# ESP32-C5 register map
Vendor: ESPRESSIF SYSTEMS (SHANGHAI) CO., LTD.; Series: ESP32 C-Series; File version: 1
CPU: RV32IMAC r0p0, little endian, no MPU, no FPU, 0 interrupt priority bits
Address unit: 32 bits
Registers are 32-bit, read-write, reset 0x0 unless marked. A register's access mark holds for its fields unless they carry their own. Offsets are from the block's base; [hi:lo] are bit positions; {n}, {i} and the like mark numbered series.

## CLINT — Core Local Interrupts
Base 0x20000000
0x1800 MSIP
  [0] MSIP — Configures the pending status of the machine software interrupt.
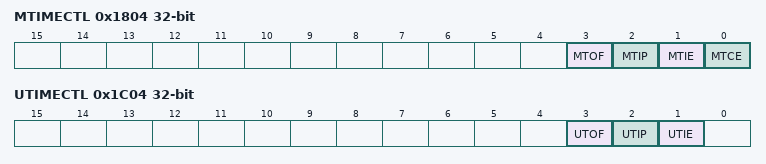
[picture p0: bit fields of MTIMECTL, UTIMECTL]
0x1804 MTIMECTL access per field
  [3] MTOF rw — Configures whether the machine timer overflows.
  [2] MTIP ro — Represents the pending status of the machine timer interrupt.
  [1] MTIE rw — Write 1 to enable the machine timer interrupt.
  [0] MTCE rw — Configures whether to enable the CLINT timer counter.
0x1808 MTIME 64-bit (reset mask 0xFFFFFFFF)
  [63:0] MTIME — Configures the 64-bit CLINT timer counter value.
0x1810 MTIMECMP 64-bit (reset mask 0xFFFFFFFF)
  [63:0] MTIMECMP — Configures the 64-bit machine timer compare value.
0x1C00 USIP
  [0] USIP — Configures the pending status of the user software interrupt.
0x1C04 UTIMECTL access per field
  [3] UTOF rw — Configures whether the user timer overflows.
  [2] UTIP ro — Represents the pending status of the user timer interrupt.
  [1] UTIE rw — Write 1 to enable the user timer interrupt.
0x1C08 UTIME 64-bit ro (reset mask 0xFFFFFFFF)
  [63:0] UTIME — Represents the read-only 64-bit CLINT timer counter value.
0x1C10 UTIMECMP 64-bit (reset mask 0xFFFFFFFF)
  [63:0] UTIMECMP — Configures the 64-bit user timer compare value.

## CLIC — Core Local Interrupt Controller
Base 0x20800000
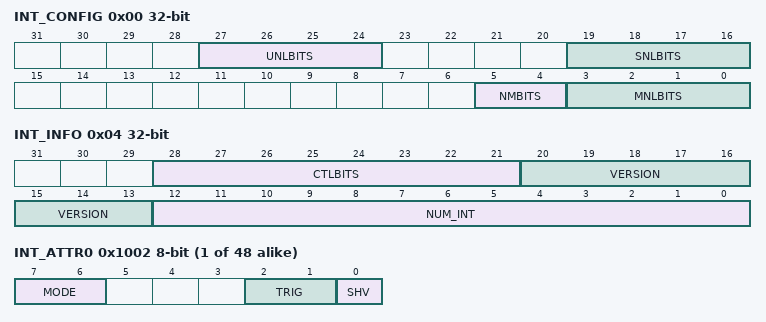
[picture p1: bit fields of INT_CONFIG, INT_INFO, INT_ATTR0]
0x00 INT_CONFIG
  [27:24] UNLBITS — User mode interrupt priority effective digits, the maximum value is 8.
  [19:16] SNLBITS — Supervisor mode interrupt priority effective digits, the maximum value is 8.
  [5:4] NMBITS — The effective number of bits in the privileged state.
  [3:0] MNLBITS — Machine mode interrupt priority effective digits, the maximum value is 8.
0x04 INT_INFO ro
  [28:21] CTLBITS — The effective bits of priority in the CLICINTCTL register.
  [20:13] VERSION — The lower 4 bits are the modified version of the hardware implementation; the upper 4 bits are the CLIC architecture version information.
  [12:0] NUM_INT — The number of interrupt sources.
{0x1000+4i} INT_IP{i} (i=0..47) 8-bit — Interrupt pending register.
  [0] INT_IP — Interrupt pending bit.
{0x1001+4i} INT_IE{i} (i=0..47) 8-bit — Interrupt enable register.
  [0] INT_IE — Interrupt enable bit.
{0x1002+4i} INT_ATTR{i} (i=0..47) 8-bit access per field — Interrupt attribute register.
  [7:6] MODE ro — Configures the privilege mode of the ith CLIC interrupt. This is hardwired to 0x3 as user mode interrupts are not supported.
  [2:1] TRIG rw — Configures the trigger type and polarity of the ith CLIC machine mode interrupt.
    0=POSITIVE_LEVEL (interrupt is positive level-triggered); 1=POSITIVE_EDGE (interrupt is positive edge-triggered); 2=NEGATIVE_LEVEL (interrupt is negative level-triggered); 3=NEGATIVE_EDGE (interrupt is negative edge-triggered)
  [0] SHV rw — Configures hardware vectoring for the ith CLIC machine mode interrupt.
    0=SOFTWARE (Not hardware vectored. Upon taking this interrupt, the CPU will jump to the address configured in mtvec.); 1=HARDWARE (Hardware vectored. Upon taking this interrupt, the CPU will jump to the word address stored at (mtvt + 4*i) relative to the base address configured in mtvt.)
{0x1003+4i} INT_CTL{i} (i=0..47) 8-bit access per field — Interrupt level control register.
  [7:5] CTL rw — Configures the level and priority of the ith CLIC machine mode interrupt.

## DS — Digital Signature
Base 0x6008C000
{0x0+4i} Y_MEM[{i}] (i=0..127) access not given — memory that stores Y
{0x200+4i} M_MEM[{i}] (i=0..127) access not given — memory that stores M
{0x400+4i} RB_MEM[{i}] (i=0..127) access not given — memory that stores Rb
{0x600+4i} BOX_MEM[{i}] (i=0..11) access not given — memory that stores BOX
{0x630+4i} IV_MEM[{i}] (i=0..3) access not given — memory that stores IV
{0x800+4i} X_MEM[{i}] (i=0..127) access not given — memory that stores X
{0xA00+4i} Z_MEM[{i}] (i=0..127) access not given — memory that stores Z
0xE00 SET_START wo — DS start control register
  [0] SET_START — set this bit to start DS operation.
0xE04 SET_CONTINUE wo — DS continue control register
  [0] SET_CONTINUE — set this bit to continue DS operation.
0xE08 SET_FINISH wo — DS finish control register
  [0] SET_FINISH — Set this bit to finish DS process.
0xE0C QUERY_BUSY ro — DS query busy register
  [0] QUERY_BUSY — digital signature state. 1'b0: idle, 1'b1: busy
0xE10 QUERY_KEY_WRONG ro — DS query key-wrong counter register
  [3:0] QUERY_KEY_WRONG — digital signature key wrong counter
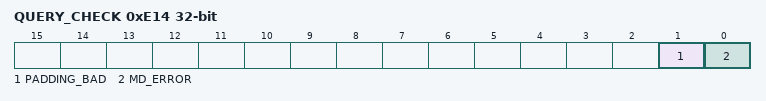
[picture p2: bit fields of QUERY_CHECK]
0xE14 QUERY_CHECK ro — DS query check result register
  [1] PADDING_BAD — padding checkout result. 1'b0: a good padding, 1'b1: a bad padding
  [0] MD_ERROR — MD checkout result. 1'b0: MD check pass, 1'b1: MD check fail
0xE20 DATE — DS version control register
